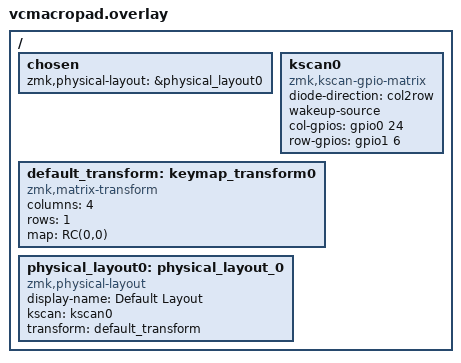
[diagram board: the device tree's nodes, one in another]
/*
 * Copyright (c) 2022 The ZMK Contributors
 *
 * SPDX-License-Identifier: MIT
 */

 #include <dt-bindings/zmk/matrix_transform.h> // Put this with the other includes at the top of your overlay

/ {
    chosen {
        zmk,physical-layout = &physical_layout0;
        // Other chosen items
    };

    kscan0: kscan0 {
        compatible = "zmk,kscan-gpio-matrix";
        diode-direction = "col2row";
        wakeup-source;

        col-gpios
            = <&gpio0 24 GPIO_ACTIVE_HIGH>
            // , <&gpio1 0 GPIO_ACTIVE_HIGH>
            // , <&gpio0 11 GPIO_ACTIVE_HIGH>
            // , <&gpio1 4 GPIO_ACTIVE_HIGH>
            ;

        row-gpios = <&gpio1 6 (GPIO_ACTIVE_HIGH | GPIO_PULL_DOWN)>;
    };

    default_transform: keymap_transform0 {
        compatible = "zmk,matrix-transform";
        columns = <4>; // Length of the "col-gpios" array
        rows = <1>; // Length of the "row-gpios" array
        map = <
        //   Key 1 | Key 2 | Key 3 | Key 4
           RC(0,0) //RC(0,1) RC(0,2) RC(0,3)
        >;
    };

    physical_layout0: physical_layout_0 { // First physical layout, use different naming for other layouts
        compatible = "zmk,physical-layout";
        display-name = "Default Layout";
        kscan = <&kscan0>; // Label of the kscan node, optional if all layouts use the same
        transform = <&default_transform>; // Label of the matrix transform for this layout
    };
};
